# R7FA8M1AH register map
Vendor: Renesas; Series: RA8; File version: 1.2
CPU: CM85 r0p0, little endian, MPU, FPU, VTOR, 4 interrupt priority bits
Registers are 32-bit, read-write, reset 0x0 unless marked. A register's access mark holds for its fields unless they carry their own. Offsets are from the block's base; [hi:lo] are bit positions.

## CPU_DBG — Debug Function
Base 0x4001B000
Same registers: CPU_DBG_NS 0x5001B000
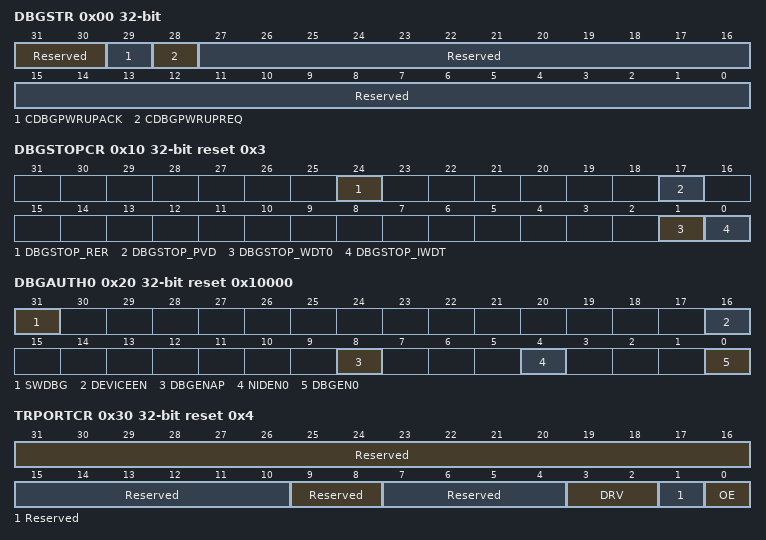
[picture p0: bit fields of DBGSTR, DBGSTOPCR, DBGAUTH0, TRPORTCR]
0x00 DBGSTR ro (reset mask 0xCFFFFFFF) — Debug Status Register
  [31:30] Reserved — These bits are read as 00.
  [29] CDBGPWRUPACK — Debug power-up acknowledge
    0=Debug power-up request is not acknowledged; 1=Debug power-up request is acknowledged
  [28] CDBGPWRUPREQ — Debug power-up request
    0=OCD is not requesting debug power-up; 1=OCD is requesting debug power-up
  [27:0] Reserved — These bits are read as 0000000000000000000000000000.
0x10 DBGSTOPCR reset 0x3 — Debug Stop Control Register
  [24] DBGSTOP_RER
    0=Enable SRAM parity/ECC error reset/interrupt; 1=Mask SRAM parity/ECC error reset/interrupt
  [17] DBGSTOP_PVD — Mask bit for PVDn (n = 1, 2) reset/interrupt
    0=Enable PVDn (n = 1, 2) reset/interrupt; 1=Mask PVDn (n = 1, 2) reset/interrupt
  [1] DBGSTOP_WDT0 — Mask bit for WDT reset/interrupt in the OCD run mode
    0=Enable WDT reset/interrupt; 1=Mask WDT reset/interrupt and stop WDT counter
  [0] DBGSTOP_IWDT — Mask bit for IWDT reset/interrupt in the OCD run mode
    0=Enable IWDT reset/interrupt; 1=Mask IWDT reset/interrupt and stop IWDT counter
0x20 DBGAUTH0 reset 0x10000 (reset mask 0x7FFFFFFF) — Debug Authentication Control Register 0
  [all] fields
    0=Disabled; 1=Enabled
  [31] SWDBG — Software control of debug function
  [16] DEVICEEN — APB-AP (AP1) authentication
  [8] DBGENAP — CPU AHB-AP (AP0) debug enable
  [4] NIDEN0 — CPU non-invasive debug enable
  [0] DBGEN0 — CPU invasive debug enable
0x24 DBGAUTH1 — Debug Authentication Control Register 1
  [8] SPIDENAP — CPU AHB-AP (AP0) debug enable
    0=Disabled; 1=Enabled
0x30 TRPORTCR reset 0x4 — Trace Port Control Register
  [31:16] Reserved — These bits are read as 0000000000000000. The write value should be 0000000000000000.
  [15:10] Reserved — These bits are read as 000000. The write value should be 000000.
  [9:8] Reserved — These bits are read as 00. The write value should be 00.
  [7:4] Reserved — These bits are read as 0000. The write value should be 0000.
  [3:2] DRV — Port Drive Capability Control indicate trace port buffer speed
    0=Low; 1=Middle; 3=Highest; 2=High
  [1] Reserved — This bit is read as 0. The write value should be 0.
  [0] OE — Data Out Enable bit indicates whether Trace Clock, Trace Data and SWO outputs are enabled or not
    0=Output disabled; 1=Output enabled
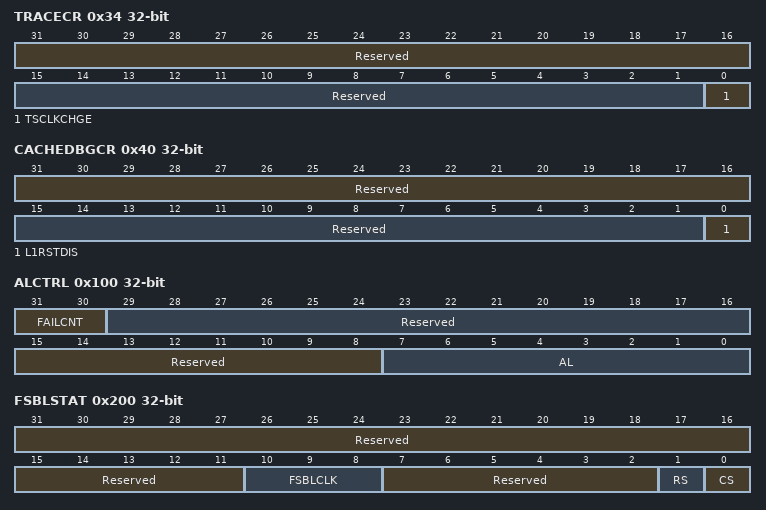
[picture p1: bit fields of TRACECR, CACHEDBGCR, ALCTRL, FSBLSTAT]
0x34 TRACECR — Trace Control Register
  [31:16] Reserved — These bits are read as 0000000000000000. The write value should be 0000000000000000.
  [15:1] Reserved — These bits are read as 000000000000000. The write value should be 000000000000000.
  [0] TSCLKCHGE — Timestamp clock ratio change is notified to trace data
    0=Disabled; 1=Enabled
0x40 CACHEDBGCR — Trace Port Control Register
  [31:16] Reserved — These bits are read as 0000000000000000. The write value should be 0000000000000000.
  [15:1] Reserved — These bits are read as 000000000000000. The write value should be 000000000000000.
  [0] L1RSTDIS — Disable L1 cache automatic invalidation
    0=Enable automatic invalidation of the L1 cache; 1=Disable automatic invalidation of the L1 cache
0x100 ALCTRL — Authentication Level Control Register
  [31:30] FAILCNT — Number of times responding incorrect response data
    0=No responding incorrect response data; 1=First time of responding incorrect response data; 2=Second time of responding incorrect response data; 3=Third time of responding incorrect response data
  [29:16] Reserved — These bits are read as 00000000000000. The write value should be 00000000000000.
  [15:8] Reserved — These bits are read as 00000000. The write value should be 00000000.
  [7:0] AL — AL monitor
    0=AL0; 5=AL1; 165=AL2
0x200 FSBLSTAT — First Stage Boot Loader Status Register
  [31:11] Reserved — These bits are read as 000000000000000000000. The write value should be 000000000000000000000.
  [10:8] FSBLCLK ro — System clock frequency selection during FSBL execution
  [7:2] Reserved — These bits are read as 000000. The write value should be 000000.
  [1] RS — FSBL result status.
    0=FSBL failed; 1=FSBL passed
  [0] CS — FSBL completion status.
    0=FSBL is executing; 1=FSBL execution is complete
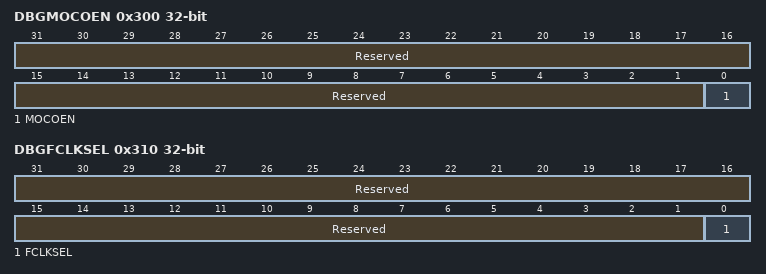
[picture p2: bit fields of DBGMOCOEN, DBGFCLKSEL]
0x300 DBGMOCOEN — MOCO Enable Request Register for Debug
  [31:1] Reserved — These bits are read as 0000000000000000000000000000000. The write value should be 0000000000000000000000000000000.
  [0] MOCOEN — MOCO enable request
    0=No request MOCO enable; 1=Request MOCO enable
0x310 DBGFCLKSEL — Flash Sequencer Clock Select Register for Debug
  [31:1] Reserved — These bits are read as 0000000000000000000000000000000. The write value should be 0000000000000000000000000000000.
  [0] FCLKSEL — Flash sequencer clock select
    0=FCLK; 1=MOCO
